# GD32W515Px register map
File version: 1.0
CPU: CM33 r0p0, little endian, MPU, FPU, 4 interrupt priority bits
Registers are 32-bit, read-write, reset 0x0 unless marked. A register's access mark holds for its fields unless they carry their own. Offsets are from the block's base; [hi:lo] are bit positions; lines under a group give offsets from that group; 'fields as' and 'values as' point back to an identical list.

## HPDF — High-Performance Digital Filter
Base 0x40016000
Same registers: SEC_HPDF 0x50016000
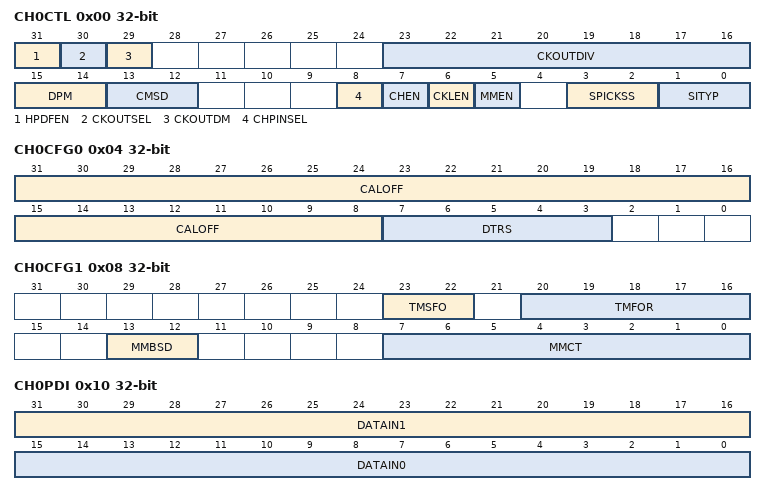
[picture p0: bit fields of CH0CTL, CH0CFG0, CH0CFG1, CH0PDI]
0x00 CH0CTL — Channel 0 control register
  [31] HPDFEN — Global enable for HPDF interface
  [30] CKOUTSEL — Serial clock output source selection
  [29] CKOUTDM — Serial clock output duty mode
  [23:16] CKOUTDIV — Serial clock output divider
  [15:14] DPM — Data packing mode
  [13:12] CMSD — Channel 0 multiplexer select input data source
  [8] CHPINSEL — Channel inputs pins selection
  [7] CHEN — Channel 0 enable
  [6] CKLEN — Clock loss detector enable
  [5] MMEN — Malfunction monitor enable
  [3:2] SPICKSS — SPI clock source select
  [1:0] SITYP — Serial interface type
0x04 CH0CFG0 — Channel 0 configuration 0 register
  [31:8] CALOFF — 24-bit calibration offset
  [7:3] DTRS — Data right bit-shift
0x08 CH0CFG1 — Channel 0 configuration 1 register
  [23:22] TMSFO — Threshold monitor Sinc filter order selection
  [20:16] TMFOR — Threshold monitor filter oversampling rate
  [13:12] MMBSD — Malfunction monitor break signal distribution
  [7:0] MMCT — Malfunction monitor counter threshold
0x0C CH0TMFDT ro — Channel 0 threshold monitor filter data register
  [15:0] TMDATA — Threshold monitor data
0x10 CH0PDI — Channel 0 parallel data input register
  [31:16] DATAIN1 — Data input 1
  [15:0] DATAIN0 — Data input 0
0x14 CH0PS — Channel 0 pulse skip register
  [5:0] PLSK — Pulses to skip for input data skipping function
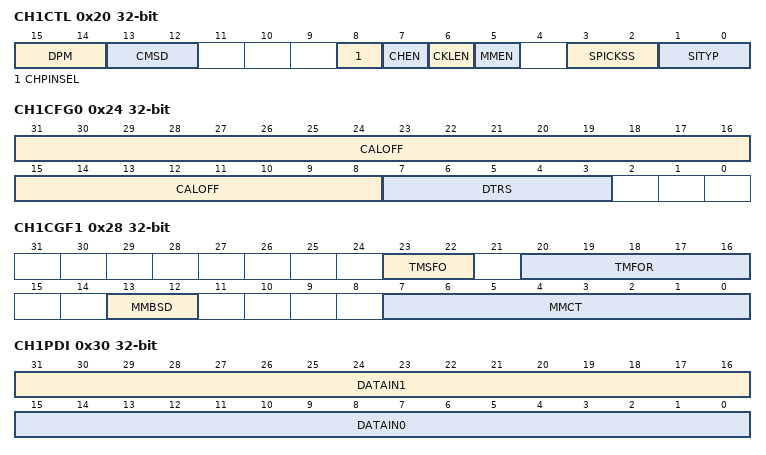
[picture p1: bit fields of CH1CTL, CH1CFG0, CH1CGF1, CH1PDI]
0x20 CH1CTL — Channel 1 control register
  [15:14] DPM — Data packing mode
  [13:12] CMSD — Channel 0 multiplexer select input data source
  [8] CHPINSEL — Channel inputs pins selection
  [7] CHEN — Channel 0 enable
  [6] CKLEN — Clock loss detector enable
  [5] MMEN — Malfunction monitor enable
  [3:2] SPICKSS — SPI clock source select
  [1:0] SITYP — Serial interface type
0x24 CH1CFG0 — Channel 1 configuration 0 register
  fields as CH0CFG0
0x28 CH1CGF1 — Channel 1 configuration 1 register
  fields as CH0CFG1
0x2C CH1TMFDT ro — Channel 0 threshold monitor filter data register
  [15:0] TMDATA — Threshold monitor data
0x30 CH1PDI — Channel 1 parallel data input register
  [31:16] DATAIN1 — Data input 1
  [15:0] DATAIN0 — Data input 0
0x34 CH1PS — Channel 1 pulse skip register
  [5:0] PLSK — Pulses to skip for input data skipping function
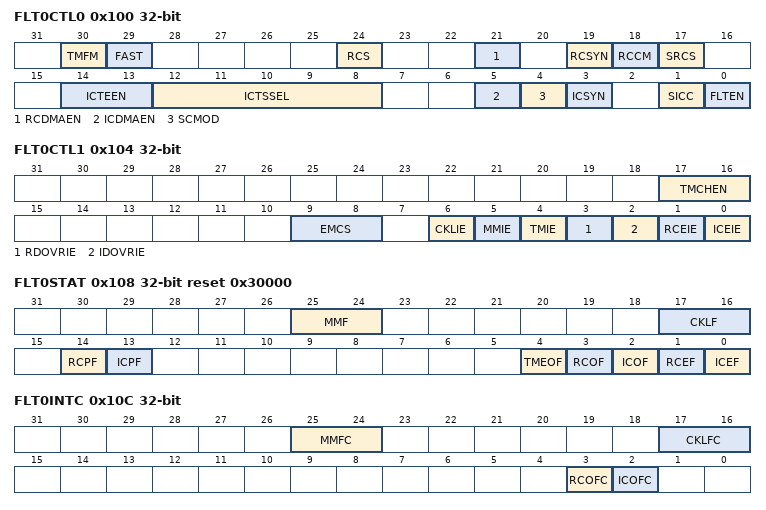
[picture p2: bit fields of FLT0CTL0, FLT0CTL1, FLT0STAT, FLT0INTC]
0x100 FLT0CTL0 — Filter 0 control register 0
  [30] TMFM — Threshold monitor fast mode
  [29] FAST — Fast conversion mode enable for regular conversions
  [24] RCS — Regular conversion channel selection
  [21] RCDMAEN — DMA channel enabled to read data for the regular conversion
  [19] RCSYN — Regular conversion synchronously
  [18] RCCM — Regular conversions continuous mode
  [17] SRCS — Start regular channel conversion by software
  [14:13] ICTEEN — Inserted conversions trigger edge enable
  [12:8] ICTSSEL — Inserted conversions trigger signal selection
  [5] ICDMAEN — DMA channel enabled to read data for the inserted channel group
  [4] SCMOD — Scan conversion mode of inserted conversions
  [3] ICSYN — Inserted conversion synchronously
  [1] SICC — Start inserted group channel conversion
  [0] FLTEN — Inserted conversions trigger signal selection
0x104 FLT0CTL1 — Filter 0 control register 1
  [17:16] TMCHEN — Threshold monitor channel enable
  [9:8] EMCS — Extremes monitor channel selection
  [6] CKLIE — Clock loss interrupt enable
  [5] MMIE — Malfunction monitor interrupt enable
  [4] TMIE — Threshold monitor interrupt enable
  [3] RDOVRIE — Regular data overflow interrupt enable
  [2] IDOVRIE — Inserted data overflow interrupt enable
  [1] RCEIE — Regular conversion end interrupt enable
  [0] ICEIE — Inserted conversion end interrupt enable
0x108 FLT0STAT ro reset 0x30000 — Filter 0 status register
  [25:24] MMF — Malfunction monitor flag
  [17:16] CKLF — Clock loss flag
  [14] RCPF — Regular conversion in progress flag
  [13] ICPF — Inserted conversion in progress flag
  [4] TMEOF — Threshold monitor event occurred flag
  [3] RCOF — Regular conversion end flag
  [2] ICOF — Inserted conversion overflow flag
  [1] RCEF — Regular conversion end flag
  [0] ICEF — Inserted conversion end flag
0x10C FLT0INTC — Filter 0 interrupt flag clear register
  [25:24] MMFC — Clear the malfunction monitor flag
  [17:16] CKLFC — Clear the clock loss flag
  [3] RCOFC — Clear the regular conversion overflow flag
  [2] ICOFC — Clear the inserted conversion overflow flag
0x110 FLT0ICGS reset 0x1 — Filter 0 inserted channel group selection register
  [1:0] ICGSEL — Inserted channel group selection
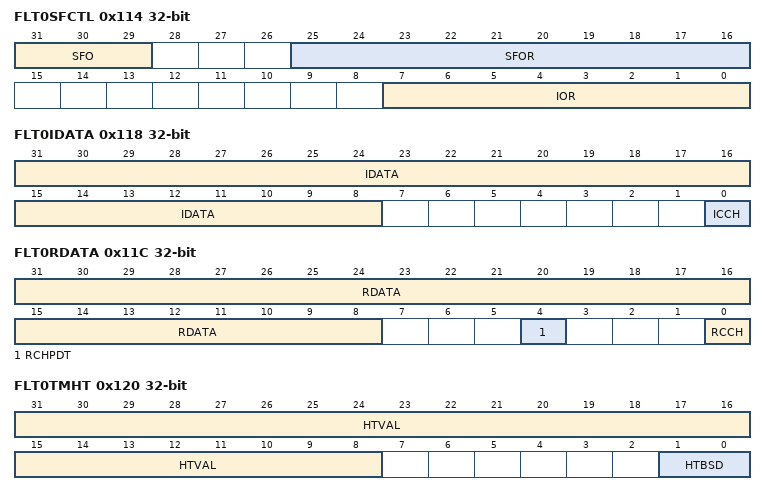
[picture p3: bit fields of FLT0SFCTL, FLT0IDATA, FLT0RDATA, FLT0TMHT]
0x114 FLT0SFCTL — Filter 0 sinc filter control register
  [31:29] SFO — Sinc filter order
  [25:16] SFOR — Sinc filter oversampling ratio
  [7:0] IOR — Integrator oversampling ratio
0x118 FLT0IDATA ro — Filter 0 inserted group data register
  [31:8] IDATA — Inserted group conversion data
  [0] ICCH — Inserted channel most recently converted
0x11C FLT0RDATA ro — Filter 0 regular channel data register
  [31:8] RDATA — Regular channel conversion data
  [4] RCHPDT — Regular channel pending data
  [0] RCCH — Regular channel most recently converted
0x120 FLT0TMHT — Filter 0 threshold monitor high threshold register
  [31:8] HTVAL — Threshold monitor high threshold value
  [1:0] HTBSD — High threshold event break signal distribution
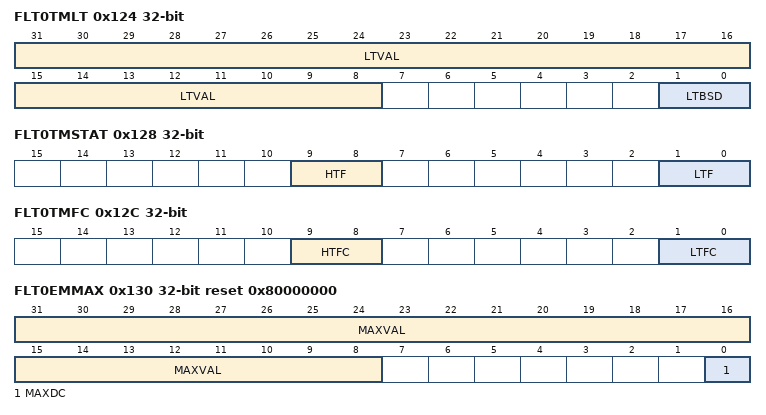
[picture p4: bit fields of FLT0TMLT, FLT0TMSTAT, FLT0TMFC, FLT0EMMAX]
0x124 FLT0TMLT — Filter 0 threshold monitor low threshold register
  [31:8] LTVAL — Threshold monitor low threshold value
  [1:0] LTBSD — Low threshold event break signal distribution
0x128 FLT0TMSTAT ro — Filter 0 threshold monitor status register
  [9:8] HTF — Threshold monitor high threshold flag
  [1:0] LTF — Threshold monitor low threshold flag
0x12C FLT0TMFC — Filter 0 threshold monitor flag clear register
  [9:8] HTFC — Clear the threshold monitor high threshold flag
  [1:0] LTFC — Clear the threshold monitor low threshold flag
0x130 FLT0EMMAX ro reset 0x80000000 — Filter 0 extremes monitor maximum register
  [31:8] MAXVAL — Extremes monitor maximum value
  [0] MAXDC — Extremes monitor maximum data channel
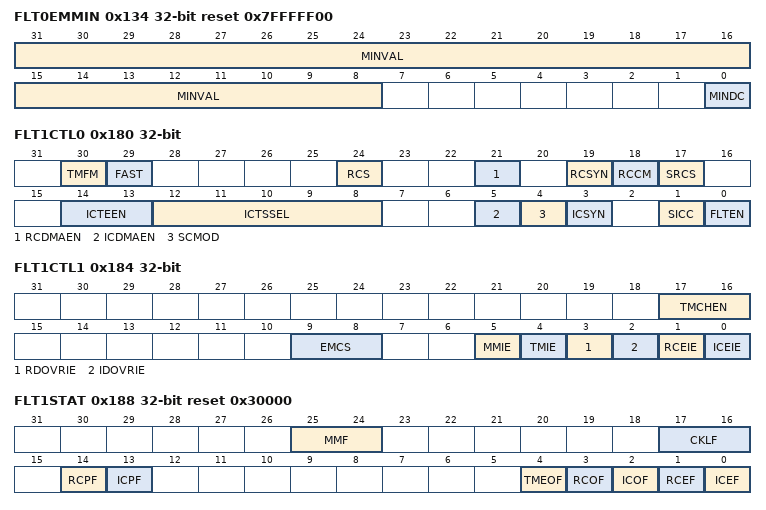
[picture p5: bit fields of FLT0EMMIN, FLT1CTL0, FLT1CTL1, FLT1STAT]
0x134 FLT0EMMIN ro reset 0x7FFFFF00 — Filter 0 extremes monitor minimum register
  [31:8] MINVAL — Extremes monitor minimum value
  [0] MINDC — Extremes monitor minimum data channel
0x180 FLT1CTL0 — Filter 1 control register 0
  fields as FLT0CTL0
0x184 FLT1CTL1 — Filter 1 control register 1
  [17:16] TMCHEN — Threshold monitor channel enable
  [9:8] EMCS — Extremes monitor channel selection
  [5] MMIE — Malfunction monitor interrupt enable
  [4] TMIE — Threshold monitor interrupt enable
  [3] RDOVRIE — Regular data overflow interrupt enable
  [2] IDOVRIE — Inserted data overflow interrupt enable
  [1] RCEIE — Regular conversion end interrupt enable
  [0] ICEIE — Inserted conversion end interrupt enable
0x188 FLT1STAT ro reset 0x30000 — Filter 1 status register
  [25:24] MMF — Malfunction monitor flag
  [17:16] CKLF — Clock loss flag
  [14] RCPF — Regular conversion in progress flag
  [13] ICPF — Inserted conversion in progress flag
  [4] TMEOF — Analog watchdog event occurred flag
  [3] RCOF — Regular conversion end flag
  [2] ICOF — Inserted conversion overflow flag
  [1] RCEF — Regular conversion end flag
  [0] ICEF — Inserted conversion end flag
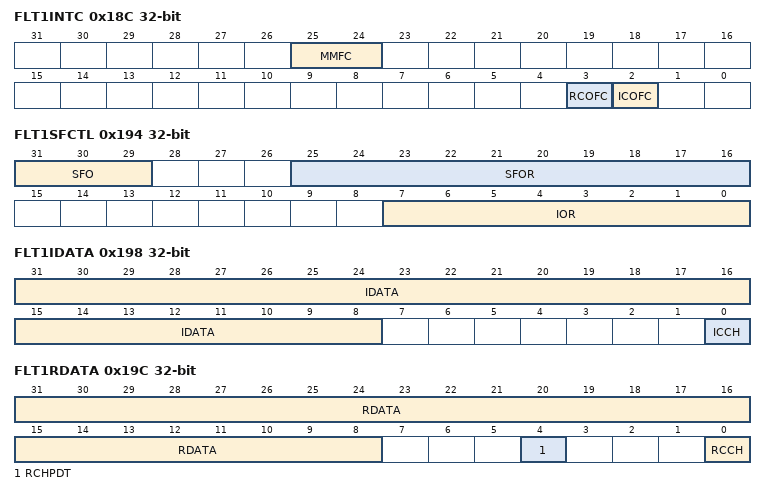
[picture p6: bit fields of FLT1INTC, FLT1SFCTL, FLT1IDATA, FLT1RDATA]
0x18C FLT1INTC — Filter 1 interrupt flag clear register
  [25:24] MMFC — Clear the short-circuit detector flag
  [3] RCOFC — Clear the regular conversion overflow flag
  [2] ICOFC — Clear the inserted conversion overflow flag
0x190 FLT1ICGS reset 0x1 — Filter 1 inserted channel group selection register
  [1:0] ICGSEL — Inserted channel group selection
0x194 FLT1SFCTL — Filter 1 sinc filter control register
  fields as FLT0SFCTL
0x198 FLT1IDATA ro — Filter 1 inserted group data register
  fields as FLT0IDATA
0x19C FLT1RDATA ro — Filter 1 regular channel data register
  fields as FLT0RDATA
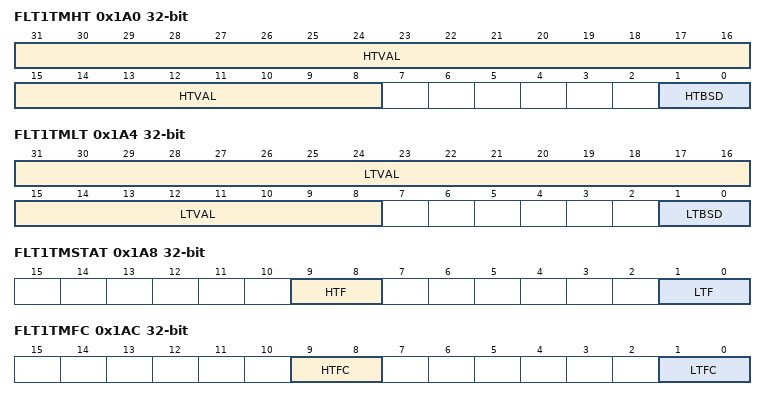
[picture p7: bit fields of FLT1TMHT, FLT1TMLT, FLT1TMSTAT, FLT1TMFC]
0x1A0 FLT1TMHT — Filter 1 threshold monitor high threshold register
  fields as FLT0TMHT
0x1A4 FLT1TMLT — Filter 1 threshold monitor low threshold register
  fields as FLT0TMLT
0x1A8 FLT1TMSTAT ro — Filter 0 threshold monitor status register
  fields as FLT0TMSTAT
0x1AC FLT1TMFC — Filter 1 threshold monitor flag clear register
  fields as FLT0TMFC
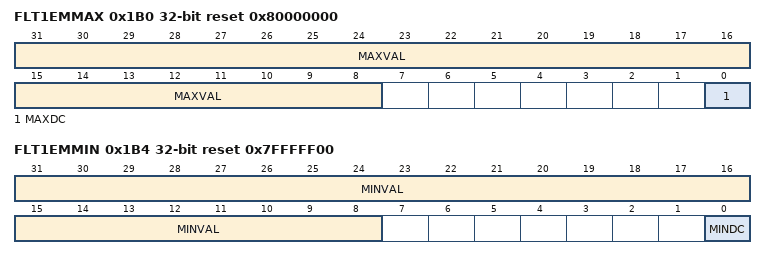
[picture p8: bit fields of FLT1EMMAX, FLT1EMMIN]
0x1B0 FLT1EMMAX ro reset 0x80000000 — Filter 1 extremes monitor maximum register
  fields as FLT0EMMAX
0x1B4 FLT1EMMIN ro reset 0x7FFFFF00 — Filter 1 extremes monitor minimum register
  fields as FLT0EMMIN
